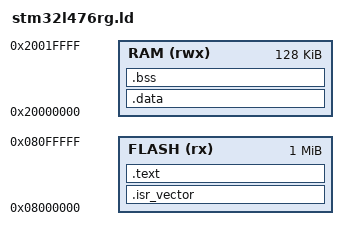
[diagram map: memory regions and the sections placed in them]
/* stm32l476rg.ld — สำหรับ STM32L476RG (1 MiB Flash, 128 KiB RAM) */

MEMORY
{
  FLASH (rx) : ORIGIN = 0x08000000, LENGTH = 1024K
  RAM   (rwx): ORIGIN = 0x20000000, LENGTH = 128K
}

ENTRY(Reset_Handler)

SECTIONS
{
  .isr_vector :
  {
    KEEP(*(.isr_vector))
  } > FLASH

  .text :
  {
    *(.text*)
    *(.rodata*)
  } > FLASH

  .data : AT(ADDR(.text) + SIZEOF(.text))
  {
    *(.data*)
  } > RAM

  .bss :
  {
    *(.bss*)
    *(COMMON)
  } > RAM

  /* stack top */
  _estack = ORIGIN(RAM) + LENGTH(RAM);
}

